# ECD3_LSE_ICONT register map
Vendor: Texas Instruments
Peripheral module from a debugger description file (folder DRA74xP_75xP_76xP_77xP).
Registers are 32-bit, access not given, reset 0x1 unless marked. A register's access mark holds for its fields unless they carry their own. Offsets are as the file gives them; lines under a group give offsets from that group; [hi:lo] are bit positions; {n}, {i} and the like mark numbered series; 'fields as' and 'values as' point back to an identical list; <NAME> marks a mode.

## ECD3_LSE_ICONT
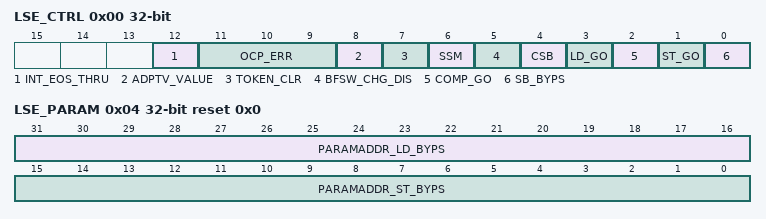
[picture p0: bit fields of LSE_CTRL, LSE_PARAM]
0x00 LSE_CTRL — Controller
  [12] INT_EOS_THRU rw — int_eos through bit 0 : LSE does the process for slice boundary after receiving int_eos. 1 : int_eos is passed through to SYNCBOX without the process for slice boundary.
  [11:9] OCP_ERR — OCP error status bit [11]: OCP DMA IP_CORE side [10]: OCP DMA SL2 side [9] : OCP CFG IP_CORE side 0: When Sresp is not ERR 1: When Sresp is ERR. Writing 0 is ignored These bits will remain 1 until RESET or until Host sets to 1. (access RW WSpecial)
  [8] ADPTV_VALUE ro — Status Adaptv_add() value This signal is cleared, if Token_clr=1.
  [7] TOKEN_CLR — LSE internal signals will be initialized to understand prologue(1st MB) as below: . -token status signal -token start/end signal -DMA pointer Writing 0 is ignored. Writing 1 will clear some internal signal. This is a self- clearing bit. The host will always read 0. If this is not used for initialization at prologue, some internal signal is kept. And also, synchronization does not function well (access W WSpecial)
  [6] SSM rw — Single Step Mode 1 : Enable Single Step Mdde 0 : Normal Mode
  [5] BFSW_CHG_DIS rw — Disabled internal BFSW change 0 : Enable internal bfsw change (default) Then, LSE controls BFSW after LD task finished. 1 : Disable BFSW change (If Host want to control BFSW with each task step by step with LD_GO, Comp_GO and ST_GO.)
  [4] CSB — Command Status Bit 0 : LSE command is defined 1 : LSE command is undefined Writing 0 is ignored These bits will remain 1 until RESET or Token_clr or until Host sets to 1. (access RW WSpecial)
  [3] LD_GO — Execute LOAD task on Byps mode Target ParamAddr_ld_byps need to set before this bit is set. 1: Execute 'LD task'. LSE access to ParamAddr_ld_byps and execute the command for LOAD task. 0 : Idle Writing 0 is ignored This bit is cleared after LD Task finished. (access RW WSpecial)
  [2] COMP_GO — Execute Comp task on Byps mode 1: Execute 'Comp task'. In the single step mode, LSE access to ParamAddr_ld_byps and execute the command for Comp task. In the normal mode, LSE executes COMP commands followed by LD commands. 0 : Idle Writing 0 is ignored This bit is cleared after Comp Task finished. (access RW WSpecial)
  [1] ST_GO — Execute Store task on Byps mode Target ParamAddr_st_byps need to set before this bit is set. 1: Execute 'Store task'. LSE access to ParamAddr_st_byps and execute the command for Store task. 0 : Idle Writing 0 is ignored This bit is cleared after ST Task finished. (access RW WSpecial)
  [0] SB_BYPS rw — Sync-Box Byps mode: 1 : LSE functions SYNCBOX bypass mode and executes the task of go_bit. 0 : LSE function normal SYNCBOX mode and waits NewTaskSignal. This value must not change during execution.
0x04 LSE_PARAM rw reset 0x0 — Parameter address for SB Bypass mode
  [31:16] PARAMADDR_LD_BYPS — Only used in the bypass mode. Address of the first command of LD and COMP sequence [128-bit word unit]. This is 128-bit word address, not byte address. The conversion from byte address to 128-bit word address must be done by CPU. IfLSE_CTRL SB_BYPS is 1, this value is used. In the bypass mode, this address is given via this field, instead via SYNCBOX And also, this field will be used on the Single Step Mode.
  [15:0] PARAMADDR_ST_BYPS — Only used in the bypass mode. Address of the first command of ST sequence [128-bit word unit]. This is 128-bit word address, not byte address. The conversion from byte address to 128-bit word address must be done by CPU. IfLSE_CTRL SB_BYPS is 1, this value is used. In the bypass mode, this address is given via this field, instead via SYNCBOX And also, this field will be used on the Single Step Mode.
